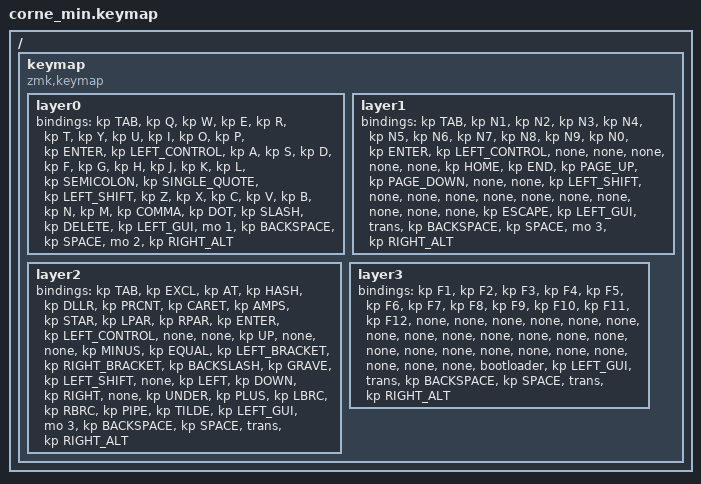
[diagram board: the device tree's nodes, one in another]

  /*
  * Copyright (c) 2020 The ZMK Contributors
  *
  * SPDX-License-Identifier: MIT
  */

  #include <behaviors.dtsi>
  #include <dt-bindings/zmk/keys.h>
  #include <dt-bindings/zmk/bt.h>
  #include <dt-bindings/zmk/ext_power.h>

  / {
    keymap {
      compatible = "zmk,keymap";
  layer0 {
          bindings = <
          &kp TAB &kp Q &kp W &kp E &kp R &kp T &kp Y &kp U &kp I &kp O &kp P &kp ENTER &kp LEFT_CONTROL &kp A &kp S &kp D &kp F &kp G &kp H &kp J &kp K &kp L &kp SEMICOLON &kp SINGLE_QUOTE &kp LEFT_SHIFT &kp Z &kp X &kp C &kp V &kp B &kp N &kp M &kp COMMA &kp DOT &kp SLASH &kp DELETE &kp LEFT_GUI &mo 1 &kp BACKSPACE &kp SPACE &mo 2 &kp RIGHT_ALT
          >;
        };layer1 {
          bindings = <
          &kp TAB &kp N1 &kp N2 &kp N3 &kp N4 &kp N5 &kp N6 &kp N7 &kp N8 &kp N9 &kp N0 &kp ENTER &kp LEFT_CONTROL &none &none &none &none &none &kp HOME &kp END &kp PAGE_UP &kp PAGE_DOWN &none &none &kp LEFT_SHIFT &none &none &none &none &none &none &none &none &none &none &kp ESCAPE &kp LEFT_GUI &trans &kp BACKSPACE &kp SPACE &mo 3 &kp RIGHT_ALT
          >;
        };layer2 {
          bindings = <
          &kp TAB &kp EXCL &kp AT &kp HASH &kp DLLR &kp PRCNT &kp CARET &kp AMPS &kp STAR &kp LPAR &kp RPAR &kp ENTER &kp LEFT_CONTROL &none &none &kp UP &none &none &kp MINUS &kp EQUAL &kp LEFT_BRACKET &kp RIGHT_BRACKET &kp BACKSLASH &kp GRAVE &kp LEFT_SHIFT &none &kp LEFT &kp DOWN &kp RIGHT &none &kp UNDER &kp PLUS &kp LBRC &kp RBRC &kp PIPE &kp TILDE &kp LEFT_GUI &mo 3 &kp BACKSPACE &kp SPACE &trans &kp RIGHT_ALT
          >;
        };layer3 {
          bindings = <
          &kp F1 &kp F2 &kp F3 &kp F4 &kp F5 &kp F6 &kp F7 &kp F8 &kp F9 &kp F10 &kp F11 &kp F12 &none &none &none &none &none &none &none &none &none &none &none &none &none &none &none &none &none &none &none &none &none &none &none &bootloader &kp LEFT_GUI &trans &kp BACKSPACE &kp SPACE &trans &kp RIGHT_ALT
          >;
        };
    };
  };
  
